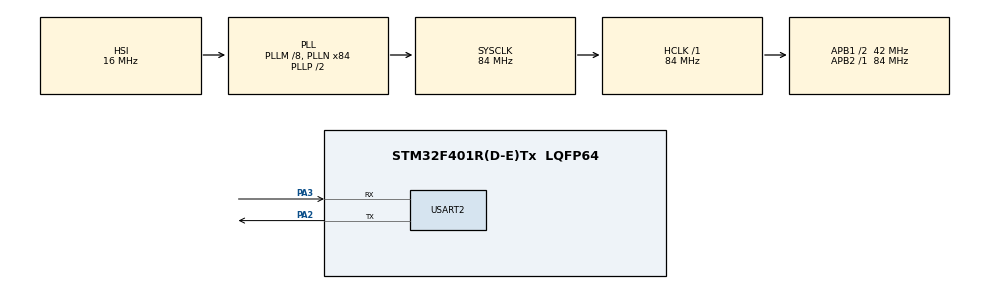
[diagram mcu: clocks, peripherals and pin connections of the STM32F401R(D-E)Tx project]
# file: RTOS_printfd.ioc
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FREERTOS.Tasks01=defaultTask,0,128,StartDefaultTask,Default,NULL,Dynamic,NULL,NULL;UARTTask,0,128,UARTStartTask,Default,NULL,Dynamic,NULL,NULL
Mcu.Family=STM32F4
Mcu.Name=STM32F401R(D-E)Tx
Mcu.Package=LQFP64
NVIC.PriorityGroup=NVIC_PRIORITYGROUP_4
NVIC.TIM1_UP_TIM10_IRQn=true\:0\:0\:false\:false\:true\:false\:false\:true
NVIC.TIM3_IRQn=true\:6\:0\:true\:false\:true\:true\:true\:true
NVIC.TimeBase=TIM1_UP_TIM10_IRQn
NVIC.TimeBaseIP=TIM10
PA2.Mode=Asynchronous
PA2.Signal=USART2_TX
PA3.Mode=Asynchronous
PA3.Signal=USART2_RX
ProjectManager.HeapSize=0x3c00
ProjectManager.StackSize=0x3c00
ProjectManager.TargetToolchain=STM32CubeIDE
RCC.48MHZClocksFreq_Value=42000000
RCC.AHBFreq_Value=84000000
RCC.APB1CLKDivider=RCC_HCLK_DIV2
RCC.APB1Freq_Value=42000000
RCC.APB1TimFreq_Value=84000000
RCC.APB2Freq_Value=84000000
RCC.APB2TimFreq_Value=84000000
RCC.CortexFreq_Value=84000000
RCC.HCLKFreq_Value=84000000
RCC.HSE_VALUE=25000000
RCC.HSI_VALUE=16000000
RCC.LSE_VALUE=32768
RCC.PLLM=8
RCC.PLLN=84
RCC.SYSCLKFreq_VALUE=84000000
RCC.SYSCLKSource=RCC_SYSCLKSOURCE_PLLCLK
RCC.VCOOutputFreq_Value=168000000
TIM3.Period=1999
TIM3.Prescaler=41999
USART2.VirtualMode=VM_ASYNC
VP_FREERTOS_VS_CMSIS_V1.Mode=CMSIS_V1
VP_SYS_VS_tim10.Mode=TIM10
VP_TIM3_VS_ClockSourceINT.Mode=Internal
board=custom

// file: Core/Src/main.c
/* USER CODE BEGIN Header */
/**
  ******************************************************************************
  * @file           : main.c
  * @brief          : Main program body
  ******************************************************************************
  * @attention
  *
  * <h2><center>&copy; Copyright (c) 2020 STMicroelectronics.
  * All rights reserved.</center></h2>
  *
  * This software component is licensed by ST under BSD 3-Clause license,
  * the "License"; You may not use this file except in compliance with the
  * License. You may obtain a copy of the License at:
  *                        opensource.org/licenses/BSD-3-Clause
  *
  ******************************************************************************
  */
/* USER CODE END Header */
#include "main.h"
#include "cmsis_os.h"

/* USER CODE BEGIN Includes */
#include <stdio.h>
#include <string.h>
/* USER CODE END Includes */

/* USER CODE BEGIN PD */
#define SIGNAL_TIM_INT 1
#define SIGNAL_UART 2
/* USER CODE END PD */

TIM_HandleTypeDef htim3;

UART_HandleTypeDef huart2;

osThreadId defaultTaskHandle;
osThreadId UARTTaskHandle;
/* USER CODE BEGIN PV */
uint8_t UARTBuf[16] = {'\0'};
/* USER CODE END PV */

void SystemClock_Config(void);
static void MX_GPIO_Init(void);
static void MX_TIM3_Init(void);
static void MX_USART2_UART_Init(void);
void StartDefaultTask(void const * argument);
void UARTStartTask(void const * argument);

int main(void)
{

  /* MCU Configuration--------------------------------------------------------*/

  /* Reset of all peripherals, Initializes the Flash interface and the Systick. */
  HAL_Init();

  /* Configure the system clock */
  SystemClock_Config();

  /* Initialize all configured peripherals */
  MX_GPIO_Init();
  MX_TIM3_Init();
  MX_USART2_UART_Init();

  /* Create the thread(s) */
  /* definition and creation of defaultTask */
  osThreadDef(defaultTask, StartDefaultTask, osPriorityNormal, 0, 128);
  defaultTaskHandle = osThreadCreate(osThread(defaultTask), NULL);

  /* definition and creation of UARTTask */
  osThreadDef(UARTTask, UARTStartTask, osPriorityNormal, 0, 128);
  UARTTaskHandle = osThreadCreate(osThread(UARTTask), NULL);

  /* Start scheduler */
  osKernelStart();

  /* We should never get here as control is now taken by the scheduler */
  /* Infinite loop */
  while (1)
  {

  }
}

void SystemClock_Config(void)
{
  RCC_OscInitTypeDef RCC_OscInitStruct = {0};
  RCC_ClkInitTypeDef RCC_ClkInitStruct = {0};

  /** Configure the main internal regulator output voltage
  */
  __HAL_RCC_PWR_CLK_ENABLE();
  __HAL_PWR_VOLTAGESCALING_CONFIG(PWR_REGULATOR_VOLTAGE_SCALE2);
  /** Initializes the RCC Oscillators according to the specified parameters
  * in the RCC_OscInitTypeDef structure.
  */
  RCC_OscInitStruct.OscillatorType = RCC_OSCILLATORTYPE_HSI;
  RCC_OscInitStruct.HSIState = RCC_HSI_ON;
  RCC_OscInitStruct.HSICalibrationValue = RCC_HSICALIBRATION_DEFAULT;
  RCC_OscInitStruct.PLL.PLLState = RCC_PLL_ON;
  RCC_OscInitStruct.PLL.PLLSource = RCC_PLLSOURCE_HSI;
  RCC_OscInitStruct.PLL.PLLM = 8;
  RCC_OscInitStruct.PLL.PLLN = 84;
  RCC_OscInitStruct.PLL.PLLP = RCC_PLLP_DIV2;
  RCC_OscInitStruct.PLL.PLLQ = 4;
  if (HAL_RCC_OscConfig(&RCC_OscInitStruct) != HAL_OK)
  {
    Error_Handler();
  }
  /** Initializes the CPU, AHB and APB buses clocks
  */
  RCC_ClkInitStruct.ClockType = RCC_CLOCKTYPE_HCLK|RCC_CLOCKTYPE_SYSCLK
                              |RCC_CLOCKTYPE_PCLK1|RCC_CLOCKTYPE_PCLK2;
  RCC_ClkInitStruct.SYSCLKSource = RCC_SYSCLKSOURCE_PLLCLK;
  RCC_ClkInitStruct.AHBCLKDivider = RCC_SYSCLK_DIV1;
  RCC_ClkInitStruct.APB1CLKDivider = RCC_HCLK_DIV2;
  RCC_ClkInitStruct.APB2CLKDivider = RCC_HCLK_DIV1;

  if (HAL_RCC_ClockConfig(&RCC_ClkInitStruct, FLASH_LATENCY_2) != HAL_OK)
  {
    Error_Handler();
  }
}

static void MX_TIM3_Init(void)
{

  TIM_ClockConfigTypeDef sClockSourceConfig = {0};
  TIM_MasterConfigTypeDef sMasterConfig = {0};

  htim3.Instance = TIM3;
  htim3.Init.Prescaler = 41999;
  htim3.Init.CounterMode = TIM_COUNTERMODE_UP;
  htim3.Init.Period = 1999;
  htim3.Init.ClockDivision = TIM_CLOCKDIVISION_DIV1;
  htim3.Init.AutoReloadPreload = TIM_AUTORELOAD_PRELOAD_DISABLE;
  if (HAL_TIM_Base_Init(&htim3) != HAL_OK)
  {
    Error_Handler();
  }
  sClockSourceConfig.ClockSource = TIM_CLOCKSOURCE_INTERNAL;
  if (HAL_TIM_ConfigClockSource(&htim3, &sClockSourceConfig) != HAL_OK)
  {
    Error_Handler();
  }
  sMasterConfig.MasterOutputTrigger = TIM_TRGO_RESET;
  sMasterConfig.MasterSlaveMode = TIM_MASTERSLAVEMODE_DISABLE;
  if (HAL_TIMEx_MasterConfigSynchronization(&htim3, &sMasterConfig) != HAL_OK)
  {
    Error_Handler();
  }

}

static void MX_USART2_UART_Init(void)
{

  huart2.Instance = USART2;
  huart2.Init.BaudRate = 115200;
  huart2.Init.WordLength = UART_WORDLENGTH_8B;
  huart2.Init.StopBits = UART_STOPBITS_1;
  huart2.Init.Parity = UART_PARITY_NONE;
  huart2.Init.Mode = UART_MODE_TX_RX;
  huart2.Init.HwFlowCtl = UART_HWCONTROL_NONE;
  huart2.Init.OverSampling = UART_OVERSAMPLING_16;
  if (HAL_UART_Init(&huart2) != HAL_OK)
  {
    Error_Handler();
  }

}

static void MX_GPIO_Init(void)
{

  /* GPIO Ports Clock Enable */
  __HAL_RCC_GPIOA_CLK_ENABLE();

}

void StartDefaultTask(void const * argument)
{
  /* USER CODE BEGIN 5 */
	HAL_TIM_Base_Start_IT(&htim3);
  /* Infinite loop */
  for(;;)
  {
	  osSignalWait(SIGNAL_TIM_INT, osWaitForever);
	  osSignalSet(UARTTaskHandle, SIGNAL_UART);
  }
  /* USER CODE END 5 */
}

void UARTStartTask(void const * argument)
{
  /* USER CODE BEGIN UARTStartTask */
	static uint16_t cnt = 0;
  /* Infinite loop */
  for(;;)
  {
	  osSignalWait(SIGNAL_UART, osWaitForever);
	  sprintf((char*)UARTBuf, "%d\n", cnt++);
	  HAL_UART_Transmit(&huart2, UARTBuf, strlen((const char *)UARTBuf), 1000);
  }
  /* USER CODE END UARTStartTask */
}

void HAL_TIM_PeriodElapsedCallback(TIM_HandleTypeDef *htim)
{
  /* USER CODE BEGIN Callback 0 */
	  if (htim->Instance == TIM3) {
		  osSignalSet(defaultTaskHandle, SIGNAL_TIM_INT);
	  }
  /* USER CODE END Callback 0 */
  if (htim->Instance == TIM10) {
    HAL_IncTick();
  }
}

void Error_Handler(void)
{
}

/************************ (C) COPYRIGHT STMicroelectronics *****END OF FILE****/
